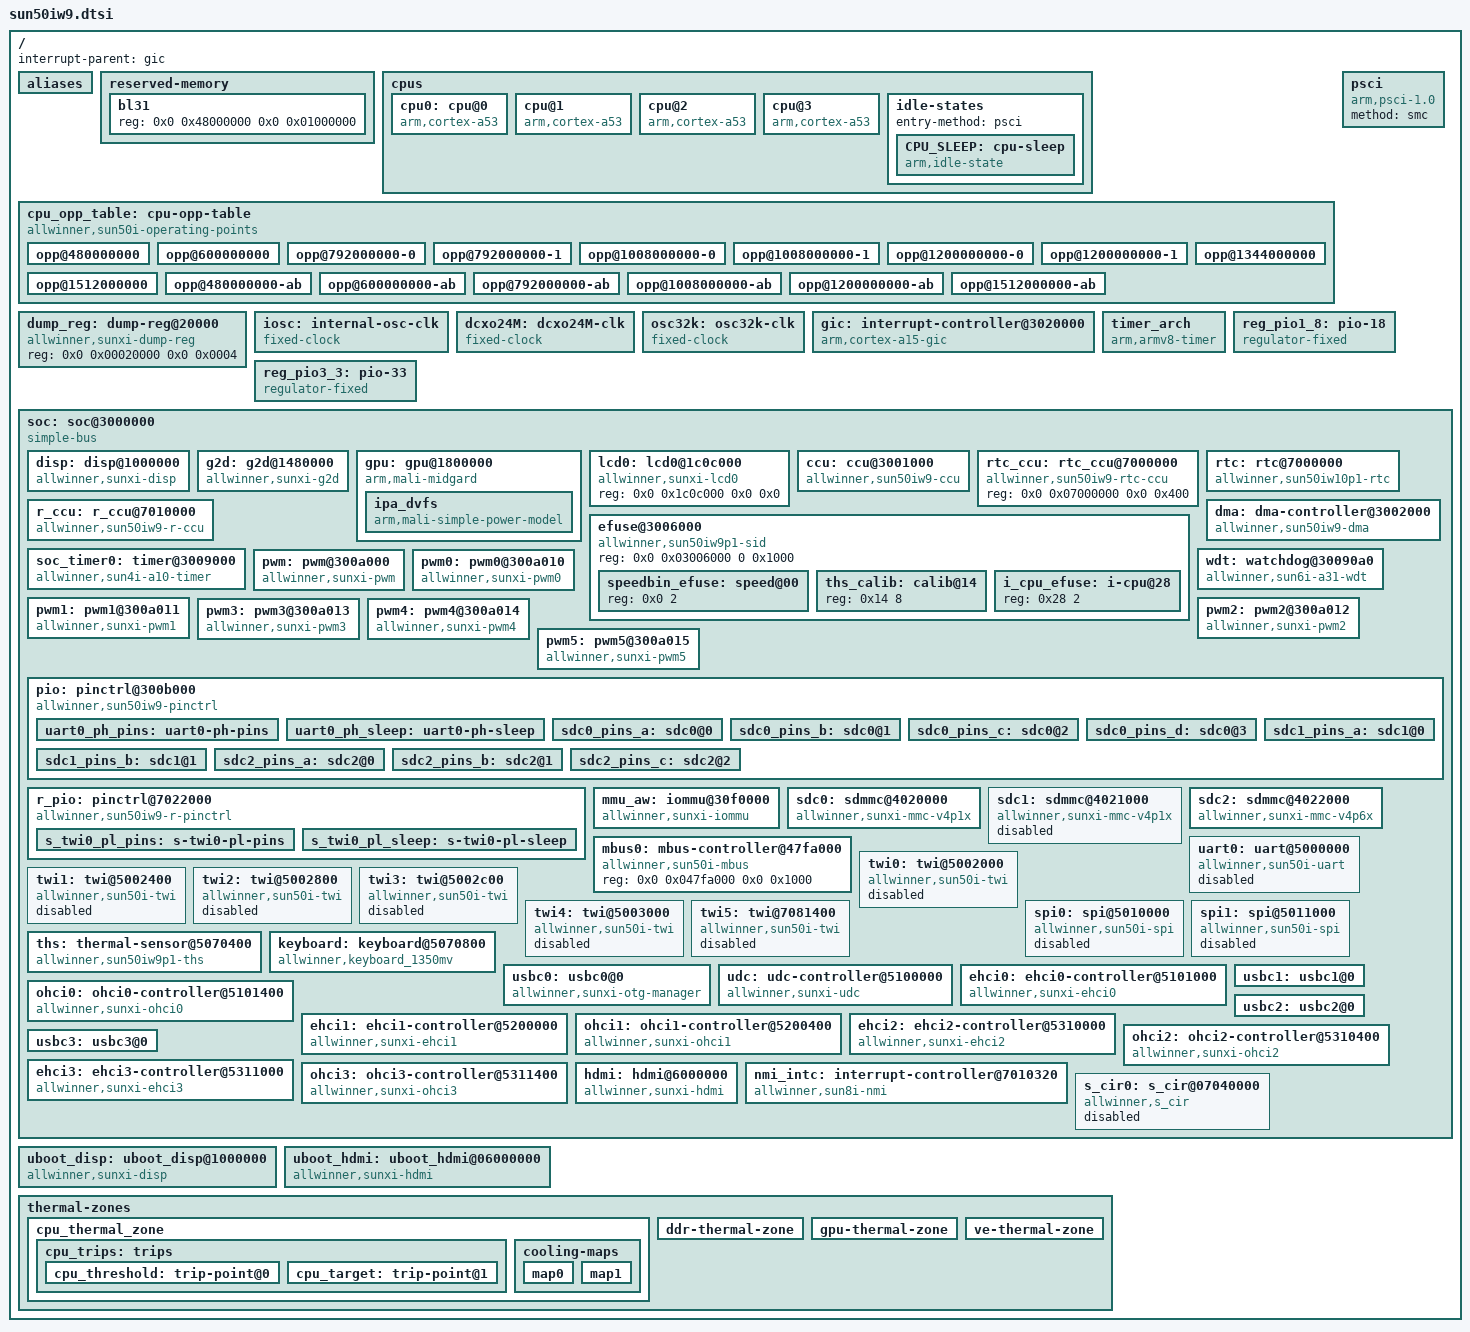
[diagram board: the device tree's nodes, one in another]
// SPDX-License-Identifier: (GPL-2.0+ or MIT)
/*
 * Copyright (C) 2020 frank@allwinnertech.com
 */

#include <dt-bindings/clock/sun50iw9-ccu.h>
#include <dt-bindings/clock/sun50iw9-ccu-rtc.h>
#include <dt-bindings/clock/sun50iw9-r-ccu.h>
#include <dt-bindings/gpio/gpio.h>
#include <dt-bindings/gpio/sun4i-gpio.h>
#include <dt-bindings/interrupt-controller/arm-gic.h>
#include <dt-bindings/reset/sun50iw9-ccu.h>
#include <dt-bindings/reset/sun50iw9-r-ccu.h>
#include <dt-bindings/thermal/thermal.h>

/ {
	interrupt-parent = <&gic>;
	#address-cells = <2>;
	#size-cells = <2>;

	aliases {
		pwm = &pwm;
		pwm0 = &pwm0;
		pwm1 = &pwm1;
		pwm2 = &pwm2;
		pwm3 = &pwm3;
		pwm4 = &pwm4;
		pwm5 = &pwm5;
		ir0 = &s_cir0;
		mmc0 = &sdc0;
		mmc2 = &sdc2;
	};

	reserved-memory {
		#address-cells = <2>;
		#size-cells = <2>;
		ranges;

		bl31 {
			reg = <0x0 0x48000000 0x0 0x01000000>;
		};
	};

	cpus {
		#address-cells = <1>;
		#size-cells = <0>;

		cpu0: cpu@0 {
			device_type = "cpu";
			compatible = "arm,cortex-a53";
			reg = <0x0>;
			enable-method = "psci";
			clocks = <&ccu CLK_CPUX>;
			operating-points-v2 = <&cpu_opp_table>;
			cpu-idle-states = <&CPU_SLEEP>;
			dynamic-power-coefficient = <202>;
			#cooling-cells = <2>;
		};

		cpu@1 {
			device_type = "cpu";
			compatible = "arm,cortex-a53";
			reg = <0x1>;
			enable-method = "psci";
			clocks = <&ccu CLK_CPUX>;
			operating-points-v2 = <&cpu_opp_table>;
			cpu-idle-states = <&CPU_SLEEP>;
			dynamic-power-coefficient = <202>;
			#cooling-cells = <2>;
		};

		cpu@2 {
			device_type = "cpu";
			compatible = "arm,cortex-a53";
			reg = <0x2>;
			enable-method = "psci";
			clocks = <&ccu CLK_CPUX>;
			operating-points-v2 = <&cpu_opp_table>;
			cpu-idle-states = <&CPU_SLEEP>;
			dynamic-power-coefficient = <202>;
			#cooling-cells = <2>;
		};

		cpu@3 {
			device_type = "cpu";
			compatible = "arm,cortex-a53";
			reg = <0x3>;
			enable-method = "psci";
			clocks = <&ccu CLK_CPUX>;
			operating-points-v2 = <&cpu_opp_table>;
			cpu-idle-states = <&CPU_SLEEP>;
			dynamic-power-coefficient = <202>;
			#cooling-cells = <2>;
		};

		idle-states {
			entry-method = "psci";

			CPU_SLEEP: cpu-sleep {
				compatible = "arm,idle-state";
				local-timer-stop;
				arm,psci-suspend-param = <0x0010000>;
				entry-latency-us = <46>;
				exit-latency-us = <59>;
				min-residency-us = <3570>;
			};
		};
	};

	cpu_opp_table: cpu-opp-table {
		compatible = "allwinner,sun50i-operating-points";
		nvmem-cells = <&speedbin_efuse>, <&i_cpu_efuse>;
		nvmem-cell-names = "speed","Icpu";
		opp-shared;

		opp@480000000 {
			opp-hz = /bits/ 64 <480000000>;
			opp-microvolt = <900000>;
			clock-latency-ns = <244144>; /* 8 32k periods */
			opp-supported-hw = <0x3>;
		};
		opp@600000000 {
			opp-hz = /bits/ 64 <600000000>;
			opp-microvolt = <900000>;
			clock-latency-ns = <244144>; /* 8 32k periods */
			opp-supported-hw = <0x3>;
		};
		opp@792000000-0 {
			opp-hz = /bits/ 64 <792000000>;
			opp-microvolt = <900000>;
			clock-latency-ns = <244144>; /* 8 32k periods */
			opp-supported-hw = <0x1>;
		};
		opp@792000000-1 {
			opp-hz = /bits/ 64 <792000000>;
			opp-microvolt = <940000>;
			clock-latency-ns = <244144>; /* 8 32k periods */
			opp-supported-hw = <0x2>;
		};
		opp@1008000000-0 {
			opp-hz = /bits/ 64 <1008000000>;
			opp-microvolt = <900000>;
			clock-latency-ns = <244144>; /* 8 32k periods */
			opp-supported-hw = <0x1>;
		};
		opp@1008000000-1 {
			opp-hz = /bits/ 64 <1008000000>;
			opp-microvolt = <1020000>;
			clock-latency-ns = <244144>; /* 8 32k periods */
			opp-supported-hw = <0x2>;
		};
		opp@1200000000-0 {
			opp-hz = /bits/ 64 <1200000000>;
			opp-microvolt = <960000>;
			clock-latency-ns = <244144>; /* 8 32k periods */
			opp-supported-hw = <0x1>;
		};
		opp@1200000000-1 {
			opp-hz = /bits/ 64 <1200000000>;
			opp-microvolt = <1100000>;
			clock-latency-ns = <244144>; /* 8 32k periods */
			opp-supported-hw = <0x2>;
		};
		opp@1344000000 {
			opp-hz = /bits/ 64 <1344000000>;
			opp-microvolt = <1120000>;
			clock-latency-ns = <244144>; /* 8 32k periods */
			opp-supported-hw = <0x2>;
		};
		opp@1512000000 {
			opp-hz = /bits/ 64 <1512000000>;
			opp-microvolt = <1100000>;
			clock-latency-ns = <244144>; /* 8 32k periods */
			opp-supported-hw = <0x1>;
		};

		opp@480000000-ab {
			opp-hz = /bits/ 64 <480000000>;
			clock-latency-ns = <244144>; /* 8 32k periods */
			opp-microvolt-a0 = <900000>;
			opp-microvolt-a1 = <900000>;
			opp-microvolt-a2 = <900000>;

			opp-microvolt-b0 = <900000>;
			opp-microvolt-b1 = <900000>;
			opp-microvolt-b2 = <900000>;
		};
		opp@600000000-ab {
			opp-hz = /bits/ 64 <600000000>;
			clock-latency-ns = <244144>; /* 8 32k periods */
			opp-microvolt-a0 = <900000>;
			opp-microvolt-a1 = <900000>;
			opp-microvolt-a2 = <900000>;

			opp-microvolt-b0 = <900000>;
			opp-microvolt-b1 = <900000>;
			opp-microvolt-b2 = <900000>;
		};
		opp@792000000-ab {
			opp-hz = /bits/ 64 <792000000>;
			clock-latency-ns = <244144>; /* 8 32k periods */
			opp-microvolt-a0 = <900000>;
			opp-microvolt-a1 = <900000>;
			opp-microvolt-a2 = <900000>;

			opp-microvolt-b0 = <900000>;
			opp-microvolt-b1 = <900000>;
			opp-microvolt-b2 = <900000>;
		};
		opp@1008000000-ab {
			opp-hz = /bits/ 64 <1008000000>;
			clock-latency-ns = <244144>; /* 8 32k periods */
			opp-microvolt-a0 = <940000>;
			opp-microvolt-a1 = <900000>;
			opp-microvolt-a2 = <900000>;

			opp-microvolt-b0 = <940000>;
			opp-microvolt-b1 = <900000>;
			opp-microvolt-b2 = <900000>;
		};
		opp@1200000000-ab {
			opp-hz = /bits/ 64 <1200000000>;
			clock-latency-ns = <244144>; /* 8 32k periods */
			opp-microvolt-a0 = <1020000>;
			opp-microvolt-a1 = <960000>;
			opp-microvolt-a2 = <960000>;

			opp-microvolt-b0 = <1020000>;
			opp-microvolt-b1 = <960000>;
			opp-microvolt-b2 = <960000>;
		};
		opp@1512000000-ab {
			opp-hz = /bits/ 64 <1512000000>;
			clock-latency-ns = <244144>; /* 8 32k periods */
			opp-microvolt-a0 = <1100000>;
			opp-microvolt-a1 = <1100000>;
			opp-microvolt-a2 = <1100000>;
		};
	};

	dump_reg: dump-reg@20000 {
		compatible = "allwinner,sunxi-dump-reg";
		reg = <0x0 0x00020000 0x0 0x0004>;
	};

	psci {
		compatible = "arm,psci-1.0";
		method = "smc";
	};

	iosc: internal-osc-clk {
		#clock-cells = <0>;
		compatible = "fixed-clock";
		clock-frequency = <16000000>;
		clock-accuracy = <300000000>;
		clock-output-names = "iosc";
	};

	dcxo24M: dcxo24M-clk {
		#clock-cells = <0>;
		compatible = "fixed-clock";
		clock-frequency = <24000000>;
		clock-output-names = "dcxo24M";
	};

	osc32k: osc32k-clk {
		#clock-cells = <0>;
		compatible = "fixed-clock";
		clock-frequency = <32768>;
		clock-output-names = "osc32k";
	};

	gic: interrupt-controller@3020000 {
		compatible = "arm,cortex-a15-gic", "arm,cortex-a9-gic";
		#interrupt-cells = <3>;
		#address-cells = <0>;
		interrupt-controller;
		reg = <0x0 0x03021000 0 0x1000>, /* GIC Dist */
		      <0x0 0x03022000 0 0x2000>, /* GIC CPU */
		      <0x0 0x03024000 0 0x2000>, /* GIC VCPU Control */
		      <0x0 0x03026000 0 0x2000>; /* GIC VCPU */
		interrupts = <GIC_PPI 9 0xf04>;  /* GIC Maintenence IRQ */
		interrupt-parent = <&gic>;
	};

	timer_arch {
		compatible = "arm,armv8-timer";
		interrupts = <GIC_PPI 13 (GIC_CPU_MASK_SIMPLE(4) | IRQ_TYPE_LEVEL_LOW)>,
			   <GIC_PPI 14 (GIC_CPU_MASK_SIMPLE(4) | IRQ_TYPE_LEVEL_LOW)>,
			   <GIC_PPI 11 (GIC_CPU_MASK_SIMPLE(4) | IRQ_TYPE_LEVEL_LOW)>,
			   <GIC_PPI 10 (GIC_CPU_MASK_SIMPLE(4) | IRQ_TYPE_LEVEL_LOW)>;
		clock-frequency = <24000000>;
		interrupt-parent = <&gic>;
		arm,no-tick-in-suspend;
	};

	reg_pio1_8: pio-18 {
		compatible = "regulator-fixed";
		regulator-name = "pio-18";
		regulator-min-microvolt = <1800000>;
		regulator-max-microvolt = <1800000>;
	};

	reg_pio3_3: pio-33 {
		compatible = "regulator-fixed";
		regulator-name = "pio-33";
		regulator-min-microvolt = <3300000>;
		regulator-max-microvolt = <3300000>;
	};

	soc: soc@3000000 {
		compatible = "simple-bus";
		#address-cells = <2>;
		#size-cells = <2>;
		ranges;

		disp: disp@1000000 {
			compatible = "allwinner,sunxi-disp";
			reg = <0x0 0x01000000 0x0 0x01400000>, /*de*/
			      <0x0 0x06510000 0x0 0x200>, /* display_if_top */
			      <0x0 0x06511000 0x0 0x1000>, /* tcon_lcd0 */
			      <0x0 0x06512000 0x0 0x1000>, /* tcon_lcd1 */
			      <0x0 0x06515000 0x0 0x1000>, /* tcon_tv0 */
			      <0x0 0x06516000 0x0 0x1000>; /* tcon_tv1 */
			interrupts = <GIC_SPI 88 IRQ_TYPE_LEVEL_HIGH>, /* DE */
				     <GIC_SPI 64 IRQ_TYPE_LEVEL_HIGH>, /* tcon_lcd0 */
				     <GIC_SPI 65 IRQ_TYPE_LEVEL_HIGH>, /* tcon_lcd1 */
				     <GIC_SPI 66 IRQ_TYPE_LEVEL_HIGH>, /* tcon_tv0 */
				     <GIC_SPI 67 IRQ_TYPE_LEVEL_HIGH>; /* tcon_tv1 */
			clocks = <&ccu CLK_DE>,
				 <&ccu CLK_DE>,
				 <&ccu CLK_BUS_DE>,
				 <&ccu CLK_BUS_DE>,
				 <&ccu CLK_TCON_LCD0>,
				 <&ccu CLK_TCON_LCD1>,
				 <&ccu CLK_TCON_TV0>,
				 <&ccu CLK_TCON_TV1>,
				 <&ccu CLK_BUS_TCON_LCD0>,
				 <&ccu CLK_BUS_TCON_LCD1>,
				 <&ccu CLK_BUS_TCON_TV0>,
				 <&ccu CLK_BUS_TCON_TV1>,
				 <&ccu CLK_BUS_DISPLAY_IF_TOP>;
			clock-names = 	"clk_de0",
					"clk_de1",
					"clk_bus_de0",
					"clk_bus_de1",
					"clk_tcon0", /* tcon lcd */
					"clk_tcon1",
					"clk_tcon2", /* tcon tv */
					"clk_tcon3",
					"clk_bus_tcon0",
					"clk_bus_tcon1",
					"clk_bus_tcon2",
					"clk_bus_tcon3",
					"clk_display_top";
			resets = <&ccu RST_BUS_DE>,
				 <&ccu RST_BUS_DE>,
				 <&ccu RST_BUS_TCON_LCD0>,
				 <&ccu RST_BUS_TCON_LCD1>,
				 <&ccu RST_BUS_TCON_TV0>,
				 <&ccu RST_BUS_TCON_TV1>,
				 <&ccu RST_BUS_LVDS>,
				 <&ccu RST_BUS_LVDS>,
				 <&ccu RST_BUS_DISPLAY_IF_TOP>;
			reset-names = 	"rst_bus_de0",
					"rst_bus_de1",
					"rst_bus_tcon0",
					"rst_bus_tcon1",
					"rst_bus_tcon2",
					"rst_bus_tcon3",
					"rst_bus_lvds0",
					"rst_bus_lvds1",
					"rst_display_top";
			assigned-clocks = <&ccu CLK_TCON_TV0>;
			assigned-clock-parents = <&ccu CLK_PLL_VIDEO2>;
			assigned-clock-rates = <0>;

			boot_disp = <0>;
			fb_base = <0>;
		};

		g2d: g2d@1480000 {
			compatible = "allwinner,sunxi-g2d";
			reg = <0x0 0x01480000 0x0 0x3ffff>;
			interrupts = <GIC_SPI 90 IRQ_TYPE_LEVEL_HIGH>;
			clocks = <&ccu CLK_BUS_G2D>, <&ccu CLK_G2D>,
				 <&ccu CLK_MBUS_G2D>;
			clock-names = "bus", "g2d", "mbus_g2d";
			resets = <&ccu RST_BUS_G2D>;
		};

		gpu: gpu@1800000 {
			device_type = "gpu";
			compatible = "arm,mali-midgard";
			reg = <0x0 0x01800000 0x0 0x10000>;
			interrupts = <GIC_SPI 95 IRQ_TYPE_LEVEL_HIGH>,
				     <GIC_SPI 96 IRQ_TYPE_LEVEL_HIGH>,
				     <GIC_SPI 97 IRQ_TYPE_LEVEL_HIGH>;
			interrupt-names = "JOB", "MMU", "GPU";
			clocks = <&ccu CLK_PLL_GPU>, <&ccu CLK_GPU0>,
				 <&ccu CLK_GPU1>,<&ccu CLK_BUS_GPU>;
			clock-names = "clk_parent", "clk_mali",
				      "clk_bak", "clk_bus";
			resets = <&ccu RST_BUS_GPU>;
			#cooling-cells = <2>;
			ipa_dvfs:ipa_dvfs {
				compatible = "arm,mali-simple-power-model";
				static-coefficient = <17000>;
				dynamic-coefficient = <750>;
				ts = <254682 9576 0xffffff98 4>;
				thermal-zone = "gpu-thermal-zone";
				ss-coefficient = <36>;
				ff-coefficient = <291>;
			};
		};

		lcd0: lcd0@1c0c000 {
			compatible = "allwinner,sunxi-lcd0";
			/* Fake registers to avoid dtc compiling warnings */
			reg = <0x0 0x1c0c000 0x0 0x0>;
			pinctrl-names = "active","sleep";
		};

		ccu: ccu@3001000 {
			compatible = "allwinner,sun50iw9-ccu";
			reg = <0x0 0x03001000 0x0 0x1000>;
			clocks = <&dcxo24M>, <&osc32k>, <&iosc>;
			clock-names = "hosc", "losc", "iosc";
			#clock-cells = <1>;
			#reset-cells = <1>;
		};

		rtc_ccu: rtc_ccu@7000000 {
			compatible = "allwinner,sun50iw9-rtc-ccu";
			reg = <0x0 0x07000000 0x0 0x400>;
			#clock-cells = <1>;
			#reset-cells = <1>;
		};

		rtc: rtc@7000000 {
			     compatible = "allwinner,sun50iw10p1-rtc";
			     device_type = "rtc";
			     wakeup-source;
			     reg = <0x0 0x07000000 0x0 0x200>;
			     interrupts = <GIC_SPI 104 IRQ_TYPE_LEVEL_HIGH>;
			     clocks = <&r_ccu CLK_R_AHB_BUS_RTC>, <&rtc_ccu CLK_RTC_1K>;
			     clock-names = "r-ahb-rtc","rtc-1k";
			     gpr_cur_pos = <6>;
		};

		r_ccu: r_ccu@7010000 {
			compatible = "allwinner,sun50iw9-r-ccu";
			reg = <0x0 0x07010000 0x0 0x300>;
			/* have no irq line */
			clocks = <&dcxo24M>, <&osc32k>, <&iosc>,
				 <&ccu CLK_PLL_PERIPH0>;
			clock-names = "hosc", "losc", "iosc", "pll-periph";
			#clock-cells = <1>;
			#reset-cells = <1>;
		};

		dma: dma-controller@3002000 {
			compatible = "allwinner,sun50iw9-dma";
			reg = <0x0 0x03002000 0x0 0x1000>;
			interrupts = <GIC_SPI 42 IRQ_TYPE_LEVEL_HIGH>;
			clocks = <&ccu CLK_BUS_DMA>, <&ccu CLK_MBUS_DMA>;
			clock-names = "bus", "mbus";
			dma-channels = <16>;
			dma-requests = <49>;
			resets = <&ccu RST_BUS_DMA>;
			#dma-cells = <1>;
		};

		efuse@3006000 {
			compatible = "allwinner,sun50iw9p1-sid";
			reg = <0x0 0x03006000 0 0x1000>;
			#address-cells = <1>;
			#size-cells = <1>;

			speedbin_efuse: speed@00 {
				reg = <0x0 2>;
			};

			ths_calib: calib@14 {
				reg = <0x14 8>;
			};

			i_cpu_efuse: i-cpu@28 {
				reg = <0x28 2>;
			};
		};

		soc_timer0: timer@3009000 {
			compatible = "allwinner,sun4i-a10-timer";
			device_type = "soc_timer";
			/*
			 * FIXME: After using sunxi timer driver, the number
			 * of CPU entering idle becomes less?
			 * "allwinner,sunxi-timer";
			 */
			reg = <0x0 0x03009000 0x0 0x400>;
			interrupt-parent = <&gic>;
			interrupts = <GIC_SPI 48 IRQ_TYPE_LEVEL_HIGH>;
			clocks = <&dcxo24M>;
		};

		wdt: watchdog@30090a0 {
			compatible = "allwinner,sun6i-a31-wdt";
			reg = <0x0 0x030090a0 0x0 0x20>;
			interrupts = <GIC_SPI 50 IRQ_TYPE_LEVEL_HIGH>;
		};

		pwm: pwm@300a000 {
			compatible = "allwinner,sunxi-pwm";
			reg = <0x0 0x0300a000 0x0 0x400>;
			clocks = <&ccu CLK_BUS_PWM>;
			resets = <&ccu RST_BUS_PWM>;
			pwm-number = <6>;
			pwm-base = <0>;
			sunxi-pwms = <&pwm0>, <&pwm1>, <&pwm2>, <&pwm3>,
				<&pwm4>, <&pwm5>;
		};

		pwm0: pwm0@300a010 {
			compatible = "allwinner,sunxi-pwm0";
			reg = <0x0 0x0300a010 0x0 0x4>;
			reg_base = <0x0300a000>;
		};

		pwm1: pwm1@300a011 {
			compatible = "allwinner,sunxi-pwm1";
			reg = <0x0 0x0300a011 0x0 0x4>;
			reg_base = <0x0300a000>;
		};

		pwm2: pwm2@300a012 {
			compatible = "allwinner,sunxi-pwm2";
			reg = <0x0 0x0300a012 0x0 0x4>;
			reg_base = <0x0300a000>;
		};

		pwm3: pwm3@300a013 {
			compatible = "allwinner,sunxi-pwm3";
			reg = <0x0 0x0300a013 0x0 0x4>;
			reg_base = <0x0300a000>;
		};

		pwm4: pwm4@300a014 {
			compatible = "allwinner,sunxi-pwm4";
			reg = <0x0 0x0300a014 0x0 0x4>;
			reg_base = <0x0300a000>;
		};

		pwm5: pwm5@300a015 {
			compatible = "allwinner,sunxi-pwm5";
			reg = <0x0 0x0300a015 0x0 0x4>;
			reg_base = <0x0300a000>;
		};

		pio: pinctrl@300b000 {
			compatible = "allwinner,sun50iw9-pinctrl";
			reg = <0x0 0x0300b000 0x0 0x400>;
			interrupts = <GIC_SPI 51 IRQ_TYPE_LEVEL_HIGH>,
				     <GIC_SPI 52 IRQ_TYPE_LEVEL_HIGH>,
				     <GIC_SPI 53 IRQ_TYPE_LEVEL_HIGH>,
				     <GIC_SPI 43 IRQ_TYPE_LEVEL_HIGH>,
				     <GIC_SPI 54 IRQ_TYPE_LEVEL_HIGH>,
				     <GIC_SPI 55 IRQ_TYPE_LEVEL_HIGH>,
				     <GIC_SPI 56 IRQ_TYPE_LEVEL_HIGH>,
				     <GIC_SPI 57 IRQ_TYPE_LEVEL_HIGH>;
			clocks = <&ccu CLK_APB1>, <&dcxo24M>, <&osc32k>;
			clock-names = "apb", "hosc", "losc";
			gpio-controller;
			#gpio-cells = <3>;
			interrupt-controller;
			#interrupt-cells = <3>;
			vcc-pf-supply = <&reg_pio1_8>;
			vcc-pfo-supply = <&reg_pio3_3>;

			uart0_ph_pins: uart0-ph-pins {
				pins = "PH0", "PH1";
				function = "uart0";
			};

			uart0_ph_sleep: uart0-ph-sleep {
				pins = "PH0", "PH1";
				function = "gpio_in";
			};

			sdc0_pins_a: sdc0@0 {
				pins = "PF0", "PF1", "PF2",
						 "PF3", "PF4", "PF5";
				function = "sdc0";
				drive-strength = <30>;
				bias-pull-up;
			};

			sdc0_pins_b: sdc0@1 {
				pins = "PF0", "PF1", "PF2",
						 "PF3", "PF4", "PF5";
				function = "gpio_in";
				bias-pull-up;
			};

			sdc0_pins_c: sdc0@2 {
				pins = "PF0", "PF1",
				       "PF3", "PF5";
				function = "jtag";
				drive-strength = <30>;
				bias-pull-up;
			};

			sdc0_pins_d: sdc0@3 {
				pins = "PF2", "PF4";
				function = "uart0";
				drive-strength = <30>;
				bias-pull-up;
			};

			sdc1_pins_a: sdc1@0 {
				pins = "PG0", "PG1", "PG2",
						 "PG3", "PG4", "PG5";
				function = "sdc1";
				drive-strength = <30>;
				bias-pull-up;
			};

			sdc1_pins_b: sdc1@1 {
				pins = "PG0", "PG1", "PG2",
						 "PG3", "PG4", "PG5";
				function = "gpio_in";
				bias-pull-up;
			};

			sdc2_pins_a: sdc2@0 {
				pins = "PC1", "PC5", "PC6",
						 "PC8", "PC9", "PC10", "PC11",
						 "PC13", "PC14", "PC15", "PC16";
				function = "sdc2";
				drive-strength = <30>;
				bias-pull-up;
			};

			sdc2_pins_b: sdc2@1 {
				pins = "PC0", "PC1", "PC5", "PC6",
						 "PC8", "PC9", "PC10", "PC11",
						 "PC13", "PC14", "PC15", "PC16";
				function = "gpio_in";
				bias-pull-up;
			};

			sdc2_pins_c: sdc2@2 {
				allwinner,pins = "PC0";
				allwinner,function = "sdc2";
				drive-strength = <30>;
				bias-pull-down;
			};
		};

		r_pio: pinctrl@7022000 {
			compatible = "allwinner,sun50iw9-r-pinctrl";
			reg = <0x0 0x07022000 0x0 0x400>;
			clocks = <&r_ccu CLK_R_APB1>, <&dcxo24M>, <&osc32k>;
			clock-names = "apb", "hosc", "losc";
			gpio-controller;
			#gpio-cells = <3>;

			s_twi0_pl_pins: s-twi0-pl-pins {
				pins = "PL0", "PL1";
				function = "s_twi0";
				drive-strength = <20>;
				bias-pull-up;
			};

			s_twi0_pl_sleep: s-twi0-pl-sleep{
				pins = "PL0", "PL1";
				function = "gpio_in";
			};
		};

		mmu_aw: iommu@30f0000 {
			compatible = "allwinner,sunxi-iommu";
			reg = <0x0 0x030f0000 0x0 0x1000>;
			interrupts = <GIC_SPI 61 IRQ_TYPE_LEVEL_HIGH>;
			interrupt-names = "iommu-irq";
			clocks = <&ccu CLK_BUS_IOMMU>;
			clock-names = "iommu";
			#iommu-cells = <2>;
		};

		sdc0: sdmmc@4020000 {
			compatible = "allwinner,sunxi-mmc-v4p1x";
			device_type = "sdc0";
			reg = <0x0 0x04020000 0x0 0x1000>;
			interrupts = <GIC_SPI 35 IRQ_TYPE_LEVEL_HIGH>;
			clocks = <&dcxo24M>,
				 <&ccu CLK_PLL_PERIPH1_2X>,
				 <&ccu CLK_MMC0>,
				 <&ccu CLK_BUS_MMC0>;
			clock-names = "osc24m","pll_periph","mmc","ahb";
			resets = <&ccu RST_BUS_MMC0>;
			reset-names = "rst";
			pinctrl-names = "default","sleep","uart_jtag";
			pinctrl-0 = <&sdc0_pins_a>;
			pinctrl-1 = <&sdc0_pins_b>;
			pinctrl-2 = <&sdc0_pins_c &sdc0_pins_d>;
			max-frequency = <50000000>;
			bus-width = <4>;
			/*non-removable;*/
			/*broken-cd;*/
			/*cd-inverted*/
			/* vmmc-supply = <&reg_3p3v>;*/
			/* vqmc-supply = <&reg_3p3v>;*/
			/* vdmc-supply = <&reg_3p3v>;*/
			cap-sd-highspeed;
			cap-wait-while-busy;
			no-sdio;
			no-mmc;
			/*sd-uhs-sdr50;*/
			/*sd-uhs-ddr50;*/
			/*cap-sdio-irq;*/
			/*keep-power-in-suspend;*/
			/*ignore-pm-notify;*/
			/*sunxi-power-save-mode;*/
			/*sunxi-dly-400k = <1 0 0 0>; */
		/*sunxi-dly-26M  = <1 0 0 0>;*/
			/*sunxi-dly-52M  = <1 0 0 0>;*/
			/*sunxi-dly-52M-ddr4  = <1 0 0 0>;*/
			/*sunxi-dly-52M-ddr8  = <1 0 0 0>;*/
			/*sunxi-dly-104M  = <1 0 0 0>;*/
			/*sunxi-dly-208M  = <1 0 0 0>;*/
			/*sunxi-dly-104M-ddr  = <1 0 0 0>;*/
			/*sunxi-dly-208M-ddr  = <1 0 0 0>;*/

			status = "okay";
		};

		sdc1: sdmmc@4021000 {
			compatible = "allwinner,sunxi-mmc-v4p1x";
			device_type = "sdc1";
			reg = <0x0 0x04021000 0x0 0x1000>;
			interrupts = <GIC_SPI 36 IRQ_TYPE_LEVEL_HIGH>;
			clocks = <&dcxo24M>,
				 <&ccu CLK_PLL_PERIPH1_2X>,
				 <&ccu CLK_MMC1>,
				 <&ccu CLK_BUS_MMC1>;
			clock-names = "osc24m","pll_periph","mmc","ahb";
			resets = <&ccu RST_BUS_MMC1>;
			reset-names = "rst";
			pinctrl-names = "default","sleep";
			pinctrl-0 = <&sdc1_pins_a>;
			pinctrl-1 = <&sdc1_pins_b>;
			max-frequency = <50000000>;
			bus-width = <4>;
			/*broken-cd;*/
			/*cd-inverted*/
			/*cd-gpios = <&pio PG 6 6 1 2 0>;*/
			/* vmmc-supply = <&reg_3p3v>;*/
			/* vqmc-supply = <&reg_3p3v>;*/
			/* vdmc-supply = <&reg_3p3v>;*/
			/*vmmc = "vcc-card";*/
			/*vqmc = "";*/
			/*vdmc = "";*/
			cap-sd-highspeed;
			no-mmc;
			/*sd-uhs-sdr50;*/
			/*sd-uhs-ddr50;*/
			/*sd-uhs-sdr104;*/
			/*cap-sdio-irq;*/
			keep-power-in-suspend;
			/*ignore-pm-notify;*/
			/*sunxi-power-save-mode;*/
			/*sunxi-dly-400k = <1 0 0 0 0>; */
			/*sunxi-dly-26M  = <1 0 0 0 0>;*/
			/*sunxi-dly-52M  = <1 0 0 0 0>;*/
			sunxi-dly-52M-ddr4  = <1 0 0 0 2>;
			/*sunxi-dly-52M-ddr8  = <1 0 0 0 0>;*/
			sunxi-dly-104M  = <1 0 0 0 1>;
			/*sunxi-dly-208M  = <1 1 0 0 0>;*/
			sunxi-dly-208M  = <1 0 0 0 1>;
			/*sunxi-dly-104M-ddr  = <1 0 0 0 0>;*/
			/*sunxi-dly-208M-ddr  = <1 0 0 0 0>;*/

			/*status = "okay";*/
			status = "disabled";
		};

		sdc2: sdmmc@4022000 {
			compatible = "allwinner,sunxi-mmc-v4p6x";
			device_type = "sdc2";
			reg = <0x0 0x04022000 0x0 0x1000>;
			interrupts = <GIC_SPI 37 IRQ_TYPE_LEVEL_HIGH>;
			clocks = <&dcxo24M>,
				 <&ccu CLK_PLL_PERIPH1_2X>,
				 <&ccu CLK_MMC2>,
				 <&ccu CLK_BUS_MMC2>;
			clock-names = "osc24m","pll_periph","mmc","ahb";
			resets = <&ccu RST_BUS_MMC2>;
			reset-names = "rst";
			pinctrl-names = "default","sleep";
			pinctrl-0 = <&sdc2_pins_a &sdc2_pins_c>;
			pinctrl-1 = <&sdc2_pins_b>;
			bus-width = <8>;
			cap-mmc-highspeed;
			cap-cmd23;
			mmc-cache-ctrl;
			non-removable;
			/*max-frequency = <200000000>;*/
			max-frequency = <50000000>;
			cap-erase;
			mmc-high-capacity-erase-size;
			no-sdio;
			no-sd;
			/*-- speed mode --*/
			/*sm0: DS26_SDR12*/
			/*sm1: HSSDR52_SDR25*/
			/*sm2: HSDDR52_DDR50*/
			/*sm3: HS200_SDR104*/
			/*sm4: HS400*/
			/*-- frequency point --*/
			/*f0: CLK_400K*/
			/*f1: CLK_25M*/
			/*f2: CLK_50M*/
			/*f3: CLK_100M*/
			/*f4: CLK_150M*/
			/*f5: CLK_200M*/

			sdc_tm4_sm0_freq0 = <0>;
			sdc_tm4_sm0_freq1 = <0>;
			sdc_tm4_sm1_freq0 = <0x00000000>;
			sdc_tm4_sm1_freq1 = <0>;
			sdc_tm4_sm2_freq0 = <0x00000000>;
			sdc_tm4_sm2_freq1 = <0>;
			sdc_tm4_sm3_freq0 = <0x05000000>;
			sdc_tm4_sm3_freq1 = <0x00000005>;
			sdc_tm4_sm4_freq0 = <0x00050000>;
			sdc_tm4_sm4_freq1 = <0x00000004>;
			sdc_tm4_sm4_freq0_cmd = <0>;
			sdc_tm4_sm4_freq1_cmd = <0>;

			/*vmmc-supply = <&reg_3p3v>;*/
			/*vqmc-supply = <&reg_3p3v>;*/
			/*vdmc-supply = <&reg_3p3v>;*/
			/*vmmc = "vcc-card";*/
			/*vqmc = "";*/
			/*vdmc = "";*/
			/*sunxi-power-save-mode;*/
			status = "okay";
		};

		mbus0: mbus-controller@47fa000 {
			compatible = "allwinner,sun50i-mbus";
			reg = <0x0 0x047fa000 0x0 0x1000>;
			#mbus-cells = <1>;
		};

		uart0: uart@5000000 {
			compatible = "allwinner,sun50i-uart";
			reg = <0x0 0x05000000 0x0 0x400>;
			interrupts = <GIC_SPI 0 IRQ_TYPE_LEVEL_HIGH>;
			clocks = <&ccu CLK_BUS_UART0>;
			resets = <&ccu RST_BUS_UART0>;
			uart0_port = <0>;
			uart0_type = <2>;
			dmas = <&dma 14>;
			dma-names = "tx";
			use_dma = <1>;
			status = "disabled";
		};

		twi0: twi@5002000 {
			#address-cells = <1>;
			#size-cells = <0>;
			compatible = "allwinner,sun50i-twi";
			device_type = "twi0";
			reg = <0x0 0x05002000 0x0 0x400>;
			interrupts = <GIC_SPI 6 IRQ_TYPE_LEVEL_HIGH>;
			clocks = <&ccu CLK_BUS_I2C0>;
			clock-names = "bus";
			resets = <&ccu RST_BUS_I2C0>;
			status = "disabled";
		};

		twi1: twi@5002400 {
			#address-cells = <1>;
			#size-cells = <0>;
			compatible = "allwinner,sun50i-twi";
			device_type = "twi1";
			reg = <0x0 0x05002400 0x0 0x400>;
			interrupts = <GIC_SPI 7 IRQ_TYPE_LEVEL_HIGH>;
			clocks = <&ccu CLK_BUS_I2C1>;
			clock-names = "bus";
			resets = <&ccu RST_BUS_I2C1>;
			status = "disabled";
		};

		twi2: twi@5002800 {
			#address-cells = <1>;
			#size-cells = <0>;
			compatible = "allwinner,sun50i-twi";
			device_type = "twi2";
			reg = <0x0 0x05002800 0x0 0x400>;
			interrupts = <GIC_SPI 8 IRQ_TYPE_LEVEL_HIGH>;
			clocks = <&ccu CLK_BUS_I2C2>;
			clock-names = "bus";
			resets = <&ccu RST_BUS_I2C2>;
			status = "disabled";
		};

		twi3: twi@5002c00 {
			#address-cells = <1>;
			#size-cells = <0>;
			compatible = "allwinner,sun50i-twi";
			device_type = "twi3";
			reg = <0x0 0x05002c00 0x0 0x400>;
			interrupts = <GIC_SPI 9 IRQ_TYPE_LEVEL_HIGH>;
			clocks = <&ccu CLK_BUS_I2C3>;
			clock-names = "bus";
			resets = <&ccu RST_BUS_I2C3>;
			status = "disabled";
		};

		twi4: twi@5003000 {
			#address-cells = <1>;
			#size-cells = <0>;
			compatible = "allwinner,sun50i-twi";
			device_type = "twi4";
			reg = <0x0 0x05003000 0x0 0x400>;
			interrupts = <GIC_SPI 10 IRQ_TYPE_LEVEL_HIGH>;
			clocks = <&ccu CLK_BUS_I2C4>;
			clock-names = "bus";
			resets = <&ccu RST_BUS_I2C4>;
			status = "disabled";
		};

		twi5: twi@7081400 {
			#address-cells = <1>;
			#size-cells = <0>;
			compatible = "allwinner,sun50i-twi";
			device_type = "twi5";
			reg = <0x0 0x07081400 0x0 0x400>;
			interrupts = <GIC_SPI 105 IRQ_TYPE_LEVEL_HIGH>;
			clocks = <&r_ccu CLK_R_APB2_I2C>;
			clock-names = "bus";
			resets = <&r_ccu RST_R_APB2_I2C>;
			status = "disabled";
		};

		spi0: spi@5010000 {
			#address-cells = <1>;
			#size-cells = <0>;
			compatible = "allwinner,sun50i-spi";
			device_type = "spi0";
			reg = <0x0 0x05010000 0x0 0x1000>;
			interrupts = <GIC_SPI 12 IRQ_TYPE_LEVEL_HIGH>;
			clocks = <&ccu CLK_PLL_PERIPH0>, <&ccu CLK_SPI0>, <&ccu CLK_BUS_SPI0>;
			clock-names = "pll", "mod", "bus";
			resets = <&ccu RST_BUS_SPI0>;
			clock-frequency = <100000000>;
			spi0_cs_number = <1>;
			spi0_cs_bitmap = <1>;
			dmas = <&dma 22>, <&dma 22>;
			dma-names = "tx", "rx";
			status = "disabled";
		};

		spi1: spi@5011000 {
			#address-cells = <1>;
			#size-cells = <0>;
			compatible = "allwinner,sun50i-spi";
			device_type = "spi1";
			reg = <0x0 0x05011000 0x0 0x1000>;
			interrupts = <GIC_SPI 13 IRQ_TYPE_LEVEL_HIGH>;
			clocks = <&ccu CLK_PLL_PERIPH0>, <&ccu CLK_SPI1>, <&ccu CLK_BUS_SPI1>;
			clock-names = "pll", "mod", "bus";
			resets = <&ccu RST_BUS_SPI1>;
			clock-frequency = <100000000>;
			spi1_cs_number = <1>;
			spi1_cs_bitmap = <1>;
			dmas = <&dma 23>, <&dma 23>;
			dma-names = "tx", "rx";
			status = "disabled";
		};

		ths: thermal-sensor@5070400 {
			compatible = "allwinner,sun50iw9p1-ths";
			reg = <0x0 0x05070400 0x0 0x400>;
			clocks = <&ccu CLK_BUS_THS>;
			clock-names = "bus";
			resets = <&ccu RST_BUS_THS>;
			nvmem-cells = <&ths_calib>;
			nvmem-cell-names = "calibration";
			#thermal-sensor-cells = <1>;
		};

		keyboard: keyboard@5070800 {
			compatible = "allwinner,keyboard_1350mv";
			reg = <0x0 0x05070800 0x0 0x400>;
			interrupts = <GIC_SPI 20 IRQ_TYPE_EDGE_RISING>;
			clocks = <&ccu CLK_BUS_LRADC>;
			resets = <&ccu RST_BUS_LRADC>;
			key_cnt = <5>;
			key0 = <212 115>;
			key1 = <409 114>;
			key2 = <473 139>;
			key3 = <525 28>;
			key4 = <576 172>;
		};

		usbc0: usbc0@0 {
			device_type = "usbc0";
			compatible = "allwinner,sunxi-otg-manager";
			usb_port_type = <2>;
			usb_detect_type = <1>;
			usb_detect_mode = <0>;
			usb_id_gpio;
			usb_det_vbus_gpio;
			usb_drv_vbus_gpio;
			usb_host_init_state = <0>;
			usb_regulator_io = "nocare";
			usb_wakeup_suspend = <0>;
			usb_luns = <3>;
			usb_serial_unique = <0>;
			usb_serial_number = "20080411";
			rndis_wceis = <1>;
		};

		udc: udc-controller@5100000 {
			compatible = "allwinner,sunxi-udc";
			reg = <0x0 0x05100000 0x0 0x1000>,
			      <0x0 0x00000000 0x0 0x100>;
			interrupts = <GIC_SPI 25 IRQ_TYPE_LEVEL_HIGH>;
			interrupt-parent = <&gic>;
			clocks = <&ccu CLK_BUS_OTG>, <&ccu CLK_USB_PHY0>;
			clock-names = "bus_otg", "phy";
			resets = <&ccu RST_BUS_OTG>, <&ccu RST_USB_PHY0>;
			reset-names = "otg", "phy";
		};

		ehci0: ehci0-controller@5101000 {
			compatible = "allwinner,sunxi-ehci0";
			reg = <0x0 0x05101000 0x0 0xFFF>,
			      <0x0 0x00000000 0x0 0x100>,
			      <0x0 0x05100000 0x0 0x1000>;
			interrupts = <GIC_SPI 26 IRQ_TYPE_LEVEL_HIGH>;
			clocks = <&ccu CLK_BUS_EHCI0>, <&ccu CLK_USB_PHY0>;
			clock-names = "bus_hci", "phy";
			resets = <&ccu RST_BUS_EHCI0>, <&ccu RST_USB_PHY0>;
			reset-names = "hci", "phy";
			hci_ctrl_no = <0>;
		};

		ohci0: ohci0-controller@5101400 {
			compatible = "allwinner,sunxi-ohci0";
			reg = <0x0 0x05101400 0x0 0xFFF>,
			      <0x0 0x00000000 0x0 0x100>,
			      <0x0 0x05100000 0x0 0x1000>;
			interrupts = <GIC_SPI 27 IRQ_TYPE_LEVEL_HIGH>;
			clocks = <&ccu CLK_BUS_OHCI0>, <&ccu CLK_USB_OHCI0>, <&ccu CLK_USB_PHY0>;
			clock-names = "bus_hci", "ohci", "phy";
			resets = <&ccu RST_BUS_OHCI0>, <&ccu RST_USB_PHY0>;
			reset-names = "hci", "phy";
			hci_ctrl_no = <0>;
		};

		usbc1: usbc1@0 {
			device_type = "usbc1";
			usb_drv_vbus_gpio;
			usb_host_init_state = <1>;
			usb_regulatior_io = "nocare";
			usb_wakeup_suspend = <0>;
		};

		ehci1: ehci1-controller@5200000 {
			compatible = "allwinner,sunxi-ehci1";
			reg = <0x0 0x05200000 0x0 0xFFF>,
			      <0x0 0x00000000 0x0 0x100>,
			      <0x0 0x05100000 0x0 0x1000>;
			interrupts = <GIC_SPI 28 IRQ_TYPE_LEVEL_HIGH>;
			clocks = <&ccu CLK_BUS_EHCI1>, <&ccu CLK_USB_PHY1>;
			clock-names = "bus_hci", "phy";
			resets = <&ccu RST_BUS_EHCI1>, <&ccu RST_USB_PHY1>;
			reset-names = "hci", "phy";
			hci_ctrl_no = <1>;
		};

		ohci1: ohci1-controller@5200400 {
			compatible = "allwinner,sunxi-ohci1";
			reg = <0x0 0x05200400 0x0 0xFFF>,
			      <0x0 0x00000000 0x0 0x100>,
			      <0x0 0x05100000 0x0 0x1000>;
			interrupts = <GIC_SPI 29 IRQ_TYPE_LEVEL_HIGH>;
			clocks = <&ccu CLK_BUS_OHCI1>, <&ccu CLK_USB_OHCI1>, <&ccu CLK_USB_PHY1>;
			clock-names = "bus_hci", "ohci", "phy";
			resets = <&ccu RST_BUS_OHCI1>, <&ccu RST_USB_PHY1>;
			reset-names = "hci", "phy";
			hci_ctrl_no = <1>;
		};

		usbc2: usbc2@0 {
			device_type = "usbc2";
			usb_drv_vbus_gpio;
			usb_host_init_state = <1>;
			usb_regulatior_io = "nocare";
			usb_wakeup_suspend = <0>;
		};

		ehci2: ehci2-controller@5310000 {
			compatible = "allwinner,sunxi-ehci2";
			reg = <0x0 0x05310000 0x0 0xFFF>,
			      <0x0 0x00000000 0x0 0x100>,
			      <0x0 0x05100000 0x0 0x1000>;
			interrupts = <GIC_SPI 30 IRQ_TYPE_LEVEL_HIGH>;
			clocks = <&ccu CLK_BUS_EHCI2>, <&ccu CLK_USB_PHY2>;
			clock-names = "bus_hci", "phy";
			resets = <&ccu RST_BUS_EHCI2>, <&ccu RST_USB_PHY2>;
			reset-names = "hci", "phy";
			hci_ctrl_no = <2>;
		};

		ohci2: ohci2-controller@5310400 {
			compatible = "allwinner,sunxi-ohci2";
			reg = <0x0 0x05310400 0x0 0xFFF>,
			      <0x0 0x00000000 0x0 0x100>,
			      <0x0 0x05100000 0x0 0x1000>;
			interrupts = <GIC_SPI 31 IRQ_TYPE_LEVEL_HIGH>;
			clocks = <&ccu CLK_BUS_OHCI2>, <&ccu CLK_USB_OHCI2>, <&ccu CLK_USB_PHY2>;
			clock-names = "bus_hci", "ohci", "phy";
			resets = <&ccu RST_BUS_OHCI2>, <&ccu RST_USB_PHY2>;
			reset-names = "hci", "phy";
			hci_ctrl_no = <2>;
		};

		usbc3: usbc3@0 {
			device_type = "usbc3";
			usb_drv_vbus_gpio;
			usb_host_init_state = <1>;
			usb_regulatior_io = "nocare";
			usb_wakeup_suspend = <0>;
		};

		ehci3: ehci3-controller@5311000 {
			compatible = "allwinner,sunxi-ehci3";
			reg = <0x0 0x05311000 0x0 0xFFF>,
			      <0x0 0x00000000 0x0 0x100>,
			      <0x0 0x05100000 0x0 0x1000>;
			interrupts = <GIC_SPI 32 IRQ_TYPE_LEVEL_HIGH>;
			clocks = <&ccu CLK_BUS_EHCI3>, <&ccu CLK_USB_PHY3>;
			clock-names = "bus_hci", "phy";
			resets = <&ccu RST_BUS_EHCI3>, <&ccu RST_USB_PHY3>;
			reset-names = "hci", "phy";
			hci_ctrl_no = <3>;
		};

		ohci3: ohci3-controller@5311400 {
			compatible = "allwinner,sunxi-ohci3";
			reg = <0x0 0x05311400 0x0 0xFFF>,
			      <0x0 0x00000000 0x0 0x100>,
			      <0x0 0x05100000 0x0 0x1000>;
			interrupts = <GIC_SPI 33 IRQ_TYPE_LEVEL_HIGH>;
			clocks = <&ccu CLK_BUS_OHCI3>, <&ccu CLK_USB_OHCI3>, <&ccu CLK_USB_PHY3>;
			clock-names = "bus_hci", "ohci", "phy";
			resets = <&ccu RST_BUS_OHCI3>, <&ccu RST_USB_PHY3>;
			reset-names = "hci", "phy";
			hci_ctrl_no = <3>;
		};

		hdmi: hdmi@6000000 {
			compatible = "allwinner,sunxi-hdmi";
			reg = <0x0 0x06000000 0x0 0x100000>;
			interrupts = <GIC_SPI 63 IRQ_TYPE_LEVEL_HIGH>;
			clocks = <&ccu CLK_BUS_HDMI>,
				<&ccu CLK_HDMI>,
				<&ccu CLK_HDMI_SLOW>,
				<&ccu CLK_HDMI_CEC>,
				<&ccu CLK_BUS_HDMI_HDCP>,
				<&ccu CLK_HDMI_HDCP>,
				<&ccu CLK_TCON_TV0>;
			clock-names = "clk_bus_hdmi",
				      "clk_hdmi",
				      "clk_ddc",
				      "clk_cec",
				      "clk_bus_hdcp",
				      "clk_hdcp",
				      "clk_tcon_tv";
			resets = <&ccu RST_BUS_HDMI_SUB>,
				<&ccu RST_BUS_HDMI_MAIN>,
				<&ccu RST_BUS_HDMI_HDCP>;
			reset-names = "rst_bus_sub",
				      "rst_bus_main",
				      "rst_bus_hdcp";
			assigned-clocks = <&ccu CLK_HDMI>,
				<&ccu CLK_HDMI_HDCP>;
			assigned-clock-parents = <&ccu CLK_PLL_VIDEO2>,
				<&ccu CLK_PLL_PERIPH1>;
			assigned-clock-rates = <0>, <0>;
		};

		nmi_intc: interrupt-controller@7010320 {
			compatible = "allwinner,sun8i-nmi";
			interrupt-controller;
			#interrupt-cells = <2>;
			reg = <0x0 0x07010320 0 0xc>;
			interrupts = <GIC_SPI 103 IRQ_TYPE_LEVEL_HIGH>;
			pad-control-v1 = <0x07000208>;
		};

		s_cir0: s_cir@07040000 {
			compatible = "allwinner,s_cir";
			reg = <0x0 0x07040000 0x0 0x400>;
			interrupts = <GIC_SPI 106 IRQ_TYPE_LEVEL_HIGH>;
			clocks = <&r_ccu CLK_R_APB1_BUS_IR>, <&dcxo24M>, <&r_ccu CLK_R_APB1_IR>;
			clock-names = "bus", "pclk", "mclk";
			resets = <&r_ccu RST_R_APB1_BUS_IR>;
			status = "disabled";
		};
	};

	uboot_disp: uboot_disp@1000000 {
		compatible = "allwinner,sunxi-disp";
		reg = <0x0 0x01000000 0x0 0x01400000>, /* de */
		      <0x0 0x06510000 0x0 0x200>, /* display_if_top */
		      <0x0 0x06511000 0x0 0x1000>, /* tcon_lcd0 */
		      <0x0 0x06512000 0x0 0x1000>, /* tcon_lcd1 */
		      <0x0 0x06515000 0x0 0x1000>, /* tcon_tv0 */
		      <0x0 0x06516000 0x0 0x1000>; /* tcon_tv1 */
		interrupts = <GIC_SPI 88 IRQ_TYPE_LEVEL_HIGH>, /* DE */
			     <GIC_SPI 64 IRQ_TYPE_LEVEL_HIGH>, /* tcon_lcd0 */
			     <GIC_SPI 65 IRQ_TYPE_LEVEL_HIGH>, /* tcon_lcd1 */
			     <GIC_SPI 66 IRQ_TYPE_LEVEL_HIGH>, /* tcon_tv0 */
			     <GIC_SPI 67 IRQ_TYPE_LEVEL_HIGH>; /* tcon_tv1 */
		clocks = <&clk_de>,
			 <&clk_display_top>,
			 <&clk_tcon_lcd>,
			 <&clk_tcon_lcd1>,
			 <&clk_tcon_tv>,
			 <&clk_tcon_tv1>,
			 <&clk_lvds>;
		boot_disp = <0>;
		fb_base = <0>;
	};

	uboot_hdmi: uboot_hdmi@06000000 {
		compatible = "allwinner,sunxi-hdmi";
		reg = <0x0 0x06000000 0x0 0x100000>;
		interrupts = <GIC_SPI 63 IRQ_TYPE_LEVEL_HIGH>;
		clocks = <&clk_hdmi>, <&clk_hdmi_slow>,
			 <&clk_hdmi_hdcp>, <&clk_hdmi_cec>;
	};

	thermal-zones{
		cpu_thermal_zone{
			polling-delay-passive = <500>;
			polling-delay = <1000>;
			thermal-sensors = <&ths 2>;
			sustainable-power = <927>;

			cpu_trips: trips{
				cpu_threshold: trip-point@0 {
					temperature = <70000>;
					type = "passive";
					hysteresis = <0>;
				};
				cpu_target: trip-point@1 {
					temperature = <90000>;
					type = "passive";
					hysteresis = <0>;
				};
			};

			cooling-maps {
				map0 {
					trip = <&cpu_target>;
					cooling-device = <&cpu0
							  THERMAL_NO_LIMIT
							  THERMAL_NO_LIMIT>;
					contribution = <1024>;
				};
				map1{
					trip = <&cpu_target>;
					cooling-device = <&gpu
							  THERMAL_NO_LIMIT
							  THERMAL_NO_LIMIT>;
					contribution = <1024>;
				};
			};
		};

		ddr-thermal-zone {
			polling-delay-passive = <0>;
			polling-delay = <0>;
			thermal-sensors = <&ths 3>;
		};

		gpu-thermal-zone {
			polling-delay-passive = <500>;
			polling-delay = <1000>;
			thermal-sensors = <&ths 0>;
			sustainable-power = <1100>;
		};

		ve-thermal-zone {
			polling-delay-passive = <0>;
			polling-delay = <0>;
			thermal-sensors = <&ths 1>;
		};
	};
};
